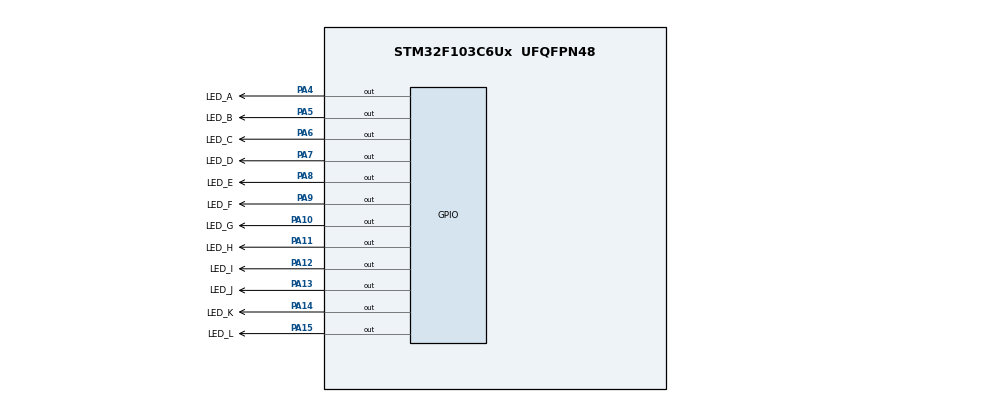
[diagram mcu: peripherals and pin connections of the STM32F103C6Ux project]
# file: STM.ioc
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Mcu.Family=STM32F1
Mcu.Name=STM32F103C6Ux
Mcu.Package=UFQFPN48
NVIC.PriorityGroup=NVIC_PRIORITYGROUP_4
PA10.GPIO_Label=LED_G
PA10.Signal=GPIO_Output
PA11.GPIO_Label=LED_H
PA11.Signal=GPIO_Output
PA12.GPIO_Label=LED_I
PA12.Signal=GPIO_Output
PA13.GPIO_Label=LED_J
PA13.Signal=GPIO_Output
PA14.GPIO_Label=LED_K
PA14.Signal=GPIO_Output
PA15.GPIO_Label=LED_L
PA15.Signal=GPIO_Output
PA4.GPIO_Label=LED_A
PA4.Signal=GPIO_Output
PA5.GPIO_Label=LED_B
PA5.Signal=GPIO_Output
PA6.GPIO_Label=LED_C
PA6.Signal=GPIO_Output
PA7.GPIO_Label=LED_D
PA7.Signal=GPIO_Output
PA8.GPIO_Label=LED_E
PA8.Signal=GPIO_Output
PA9.GPIO_Label=LED_F
PA9.Signal=GPIO_Output
ProjectManager.HeapSize=0x200
ProjectManager.StackSize=0x400
ProjectManager.TargetToolchain=STM32CubeIDE
RCC.APB1Freq_Value=8000000
RCC.APB2Freq_Value=8000000
VP_SYS_VS_ND.Mode=No_Debug
board=custom

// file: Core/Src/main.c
/* USER CODE BEGIN Header */
/**
  ******************************************************************************
  * @file           : main.c
  * @brief          : Main program body
  ******************************************************************************
  * @attention
  *
  * <h2><center>&copy; Copyright (c) 2022 STMicroelectronics.
  * All rights reserved.</center></h2>
  *
  * This software component is licensed by ST under BSD 3-Clause license,
  * the "License"; You may not use this file except in compliance with the
  * License. You may obtain a copy of the License at:
  *                        opensource.org/licenses/BSD-3-Clause
  *
  ******************************************************************************
  */
/* USER CODE END Header */
#include "main.h"
#include <math.h>

/* USER CODE BEGIN PTD */
enum LedState { RED_STATE , YELLOW_STATE , GREEN_STATE } ;
/* USER CODE END PTD */

/* USER CODE BEGIN PD */
#define LEDS_NUMBER 12
#define SECOND 1000
#define LAST_LEDS_ARR_INDEX 11
#define LED_STATE_LEVEL 5
/* USER CODE END PD */

void SystemClock_Config(void);
static void MX_GPIO_Init(void);

int leds_array[LEDS_NUMBER] = {LED_A_Pin,LED_B_Pin,LED_C_Pin,LED_D_Pin,LED_E_Pin,LED_F_Pin,LED_G_Pin,LED_H_Pin,LED_I_Pin,LED_J_Pin,LED_K_Pin,LED_L_Pin};
void clearAllClock(){
	for(int i = 0; i < LEDS_NUMBER; i++){
		HAL_GPIO_WritePin(GPIOA, leds_array[i], GPIO_PIN_SET);
	}
}

void setNumberOnClock(int num){
	HAL_GPIO_WritePin(GPIOA, leds_array[num], GPIO_PIN_RESET);
}

void clearNumberOnClock(int num){
	HAL_GPIO_WritePin(GPIOA, leds_array[num], GPIO_PIN_SET);
}

void runClock(int* second, int* min, int* hour){
   //Format numbers, clear old state led
   if(*second == 59){
	   *second = 0;
	   clearNumberOnClock(LAST_LEDS_ARR_INDEX);
	   if(*min == 59){
		   *min = 0;
		   clearNumberOnClock(*hour%LEDS_NUMBER);
		   (*hour)++;
	   }else (*min)++;
   }else (*second)++;

   if(*hour >= 24) *hour = 0;

   // clear old state led
   if(*second != 0 && *second % LED_STATE_LEVEL == 0){
   	   clearNumberOnClock(floor(*second/LED_STATE_LEVEL)-1);
      }
      if(*min != 0 && *min % LED_STATE_LEVEL == 0){
   		   clearNumberOnClock(floor(*min/LED_STATE_LEVEL)-1);
      }
}
int main(void)
{

  /* MCU Configuration--------------------------------------------------------*/

  /* Reset of all peripherals, Initializes the Flash interface and the Systick. */
  HAL_Init();

  /* Configure the system clock */
  SystemClock_Config();

  /* Initialize all configured peripherals */
  MX_GPIO_Init();

  /* Infinite loop */
  /* USER CODE BEGIN WHILE */

// for ex6
//  int led_index = 0;
  clearAllClock();

  //For Ex10
  int hour = 1;
  int minute = 59;
  int second = 50;
  while (1)
  {
//
//  	   Testing Ex6:
//	   	   HAL_GPIO_WritePin(GPIOA, leds_array[led_index], GPIO_PIN_RESET);
//		   led_index = (led_index + 1);
//		   HAL_Delay(SECOND);

//	 	   Testing Ex8:
//	 	   setNumberOnClock(4);
//	 	   HAL_Delay(SECOND);

//	   	   Testing Ex9:
//		   setNumberOnClock(4);
//		   HAL_Delay(SECOND);
//		   clearNumberOnClock(4);
//		   HAL_Delay(SECOND);

//	      Testing Ex10:
		  setNumberOnClock(hour % LEDS_NUMBER);
		  setNumberOnClock((int)floor(minute / LED_STATE_LEVEL));
		  setNumberOnClock((int)floor(second / LED_STATE_LEVEL));
		  HAL_Delay(10);
		  runClock(&second, &minute, &hour);

    /* USER CODE END WHILE */

  }
}

void SystemClock_Config(void)
{
  RCC_OscInitTypeDef RCC_OscInitStruct = {0};
  RCC_ClkInitTypeDef RCC_ClkInitStruct = {0};

  /** Initializes the RCC Oscillators according to the specified parameters
  * in the RCC_OscInitTypeDef structure.
  */
  RCC_OscInitStruct.OscillatorType = RCC_OSCILLATORTYPE_HSI;
  RCC_OscInitStruct.HSIState = RCC_HSI_ON;
  RCC_OscInitStruct.HSICalibrationValue = RCC_HSICALIBRATION_DEFAULT;
  RCC_OscInitStruct.PLL.PLLState = RCC_PLL_NONE;
  if (HAL_RCC_OscConfig(&RCC_OscInitStruct) != HAL_OK)
  {
    Error_Handler();
  }
  /** Initializes the CPU, AHB and APB buses clocks
  */
  RCC_ClkInitStruct.ClockType = RCC_CLOCKTYPE_HCLK|RCC_CLOCKTYPE_SYSCLK
                              |RCC_CLOCKTYPE_PCLK1|RCC_CLOCKTYPE_PCLK2;
  RCC_ClkInitStruct.SYSCLKSource = RCC_SYSCLKSOURCE_HSI;
  RCC_ClkInitStruct.AHBCLKDivider = RCC_SYSCLK_DIV1;
  RCC_ClkInitStruct.APB1CLKDivider = RCC_HCLK_DIV1;
  RCC_ClkInitStruct.APB2CLKDivider = RCC_HCLK_DIV1;

  if (HAL_RCC_ClockConfig(&RCC_ClkInitStruct, FLASH_LATENCY_0) != HAL_OK)
  {
    Error_Handler();
  }
}

static void MX_GPIO_Init(void)
{
  GPIO_InitTypeDef GPIO_InitStruct = {0};

  /* GPIO Ports Clock Enable */
  __HAL_RCC_GPIOA_CLK_ENABLE();

  /*Configure GPIO pin Output Level */
  HAL_GPIO_WritePin(GPIOA, LED_A_Pin|LED_B_Pin|LED_C_Pin|LED_D_Pin
                          |LED_E_Pin|LED_F_Pin|LED_G_Pin|LED_H_Pin
                          |LED_I_Pin|LED_J_Pin|LED_K_Pin|LED_L_Pin, GPIO_PIN_RESET);

  /*Configure GPIO pins : LED_A_Pin LED_B_Pin LED_C_Pin LED_D_Pin
                           LED_E_Pin LED_F_Pin LED_G_Pin LED_H_Pin
                           LED_I_Pin LED_J_Pin LED_K_Pin LED_L_Pin */
  GPIO_InitStruct.Pin = LED_A_Pin|LED_B_Pin|LED_C_Pin|LED_D_Pin
                          |LED_E_Pin|LED_F_Pin|LED_G_Pin|LED_H_Pin
                          |LED_I_Pin|LED_J_Pin|LED_K_Pin|LED_L_Pin;
  GPIO_InitStruct.Mode = GPIO_MODE_OUTPUT_PP;
  GPIO_InitStruct.Pull = GPIO_NOPULL;
  GPIO_InitStruct.Speed = GPIO_SPEED_FREQ_LOW;
  HAL_GPIO_Init(GPIOA, &GPIO_InitStruct);

}

void Error_Handler(void)
{
  __disable_irq();
  while (1)
  {
  }
}

/************************ (C) COPYRIGHT STMicroelectronics *****END OF FILE****/
